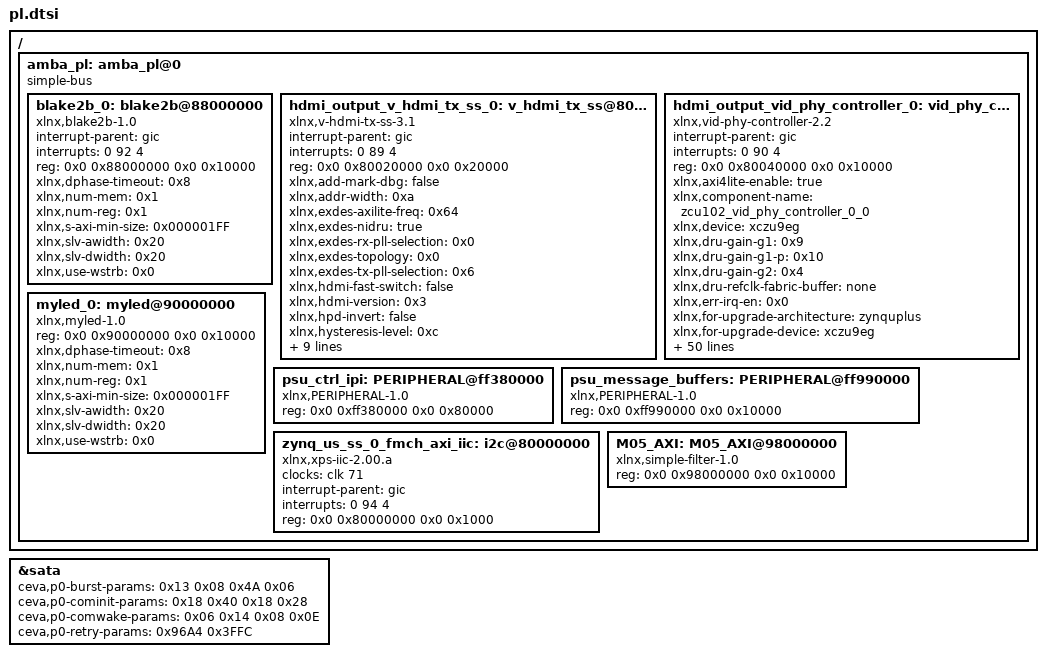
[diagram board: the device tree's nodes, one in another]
/*
 * CAUTION: This file is automatically generated by Xilinx.
 * Version:  
 * Today is: Wed Sep 23 01:31:24 2020
 */


/ {
	amba_pl: amba_pl@0 {
		#address-cells = <2>;
		#size-cells = <2>;
		compatible = "simple-bus";
		ranges ;
		blake2b_0: blake2b@88000000 {
			compatible = "xlnx,blake2b-1.0";
			interrupt-names = "Interrupt";
			interrupt-parent = <&gic>;
			interrupts = <0 92 4>;
			reg = <0x0 0x88000000 0x0 0x10000>;
			xlnx,dphase-timeout = <0x8>;
			xlnx,num-mem = <0x1>;
			xlnx,num-reg = <0x1>;
			xlnx,s-axi-min-size = <0x000001FF>;
			xlnx,slv-awidth = <0x20>;
			xlnx,slv-dwidth = <0x20>;
			xlnx,use-wstrb = <0x0>;
		};
		hdmi_output_v_hdmi_tx_ss_0: v_hdmi_tx_ss@80020000 {
			compatible = "xlnx,v-hdmi-tx-ss-3.1";
			interrupt-names = "irq";
			interrupt-parent = <&gic>;
			interrupts = <0 89 4>;
			reg = <0x0 0x80020000 0x0 0x20000>;
			xlnx,add-mark-dbg = "false";
			xlnx,addr-width = <0xa>;
			xlnx,exdes-axilite-freq = <0x64>;
			xlnx,exdes-nidru = "true";
			xlnx,exdes-rx-pll-selection = <0x0>;
			xlnx,exdes-topology = <0x0>;
			xlnx,exdes-tx-pll-selection = <0x6>;
			xlnx,hdmi-fast-switch = "false";
			xlnx,hdmi-version = <0x3>;
			xlnx,hpd-invert = "false";
			xlnx,hysteresis-level = <0xc>;
			xlnx,include-hdcp-1-4 = "false";
			xlnx,include-hdcp-2-2 = "false";
			xlnx,include-low-reso-vid = "false";
			xlnx,include-yuv420-sup = "false";
			xlnx,input-pixels-per-clock = <0x2>;
			xlnx,max-bits-per-component = <0x8>;
			xlnx,validation-enable = "false";
			xlnx,vid-interface = <0x0>;
			xlnx,video-mask-enable = <0x1>;
		};
		hdmi_output_vid_phy_controller_0: vid_phy_controller@80040000 {
			compatible = "xlnx,vid-phy-controller-2.2";
			interrupt-names = "irq";
			interrupt-parent = <&gic>;
			interrupts = <0 90 4>;
			reg = <0x0 0x80040000 0x0 0x10000>;
			xlnx,axi4lite-enable = "true";
			xlnx,component-name = "zcu102_vid_phy_controller_0_0";
			xlnx,device = "xczu9eg";
			xlnx,dru-gain-g1 = <0x9>;
			xlnx,dru-gain-g1-p = <0x10>;
			xlnx,dru-gain-g2 = <0x4>;
			xlnx,dru-refclk-fabric-buffer = "none";
			xlnx,err-irq-en = <0x0>;
			xlnx,for-upgrade-architecture = "zynquplus";
			xlnx,for-upgrade-device = "xczu9eg";
			xlnx,for-upgrade-maxoptvol = "0.876";
			xlnx,for-upgrade-package = "ffvb1156";
			xlnx,for-upgrade-part = "xczu9eg-ffvb1156-2-e";
			xlnx,for-upgrade-refvol = "0.850";
			xlnx,for-upgrade-speedgrade = "-2";
			xlnx,hdmi-fast-switch = <0x1>;
			xlnx,input-pixels-per-clock = <0x2>;
			xlnx,int-hdmi-ver-cmptble = <0x3>;
			xlnx,nidru = <0x0>;
			xlnx,nidru-refclk-sel = <0x0>;
			xlnx,rx-gt-debug-ports = "false";
			xlnx,rx-no-of-channels = <0x3>;
			xlnx,rx-outclk-buffer = "none";
			xlnx,rx-pll-selection = <0x0>;
			xlnx,rx-protocol = <0x3>;
			xlnx,rx-refclk-sel = <0x1>;
			xlnx,rx-sb-ports = "true";
			xlnx,rx-tmds-clk-buffer = "bufg";
			xlnx,rx-video-clk-buffer = "bufg";
			xlnx,silicon-revision = <0x0>;
			xlnx,speedgrade = "-2";
			xlnx,supportlevel = <0x1>;
			xlnx,transceivercontrol = "false";
			xlnx,tx-gt-debug-ports = "false";
			xlnx,tx-no-of-channels = <0x3>;
			xlnx,tx-outclk-buffer = "none";
			xlnx,tx-pll-selection = <0x6>;
			xlnx,tx-protocol = <0x1>;
			xlnx,tx-refclk-fabric-buffer = "none";
			xlnx,tx-refclk-sel = <0x0>;
			xlnx,tx-sb-ports = "true";
			xlnx,tx-tmds-clk-buffer = "bufg";
			xlnx,tx-video-clk-buffer = "bufg";
			xlnx,txpi-port-en = "false";
			xlnx,txrefclk-rdy-invert = <0x1>;
			xlnx,use-gt-ch4-hdmi = <0x0>;
			xlnx,use-oddr-for-tmds-clkout = "true";
			xlnx,vid-phy-axi4lite-addr-width = <0xa>;
			xlnx,vid-phy-axi4lite-data-width = <0x20>;
			xlnx,vid-phy-control-sb-rx-tdata-width = <0x1>;
			xlnx,vid-phy-control-sb-tx-tdata-width = <0x1>;
			xlnx,vid-phy-rx-axi4s-ch-int-tdata-width = <0x14>;
			xlnx,vid-phy-rx-axi4s-ch-tdata-width = <0x14>;
			xlnx,vid-phy-rx-axi4s-ch-tuser-width = <0x1>;
			xlnx,vid-phy-status-sb-rx-tdata-width = <0x1>;
			xlnx,vid-phy-status-sb-tx-tdata-width = <0x2>;
			xlnx,vid-phy-tx-axi4s-ch-int-tdata-width = <0x14>;
			xlnx,vid-phy-tx-axi4s-ch-tdata-width = <0x14>;
			xlnx,vid-phy-tx-axi4s-ch-tuser-width = <0x1>;
			xlnx,viper-reg = "false";
		};
		myled_0: myled@90000000 {
			compatible = "xlnx,myled-1.0";
			reg = <0x0 0x90000000 0x0 0x10000>;
			xlnx,dphase-timeout = <0x8>;
			xlnx,num-mem = <0x1>;
			xlnx,num-reg = <0x1>;
			xlnx,s-axi-min-size = <0x000001FF>;
			xlnx,slv-awidth = <0x20>;
			xlnx,slv-dwidth = <0x20>;
			xlnx,use-wstrb = <0x0>;
		};
		psu_ctrl_ipi: PERIPHERAL@ff380000 {
			compatible = "xlnx,PERIPHERAL-1.0";
			reg = <0x0 0xff380000 0x0 0x80000>;
		};
		psu_message_buffers: PERIPHERAL@ff990000 {
			compatible = "xlnx,PERIPHERAL-1.0";
			reg = <0x0 0xff990000 0x0 0x10000>;
		};
		zynq_us_ss_0_fmch_axi_iic: i2c@80000000 {
			#address-cells = <1>;
			#size-cells = <0>;
			clock-names = "s_axi_aclk";
			clocks = <&clk 71>;
			compatible = "xlnx,xps-iic-2.00.a";
			interrupt-names = "iic2intc_irpt";
			interrupt-parent = <&gic>;
			interrupts = <0 94 4>;
			reg = <0x0 0x80000000 0x0 0x1000>;
		};
		M05_AXI: M05_AXI@98000000 {
			reg = <0x0 0x98000000 0x0 0x10000>;
			compatible = "xlnx,simple-filter-1.0";
		};
	};
};
&sata {
	ceva,p0-burst-params = /bits/ 8 <0x13 0x08 0x4A 0x06>;
	ceva,p0-cominit-params = /bits/ 8 <0x18 0x40 0x18 0x28>;
	ceva,p0-comwake-params = /bits/ 8 <0x06 0x14 0x08 0x0E>;
	ceva,p0-retry-params = /bits/ 16 <0x96A4 0x3FFC>;
};
